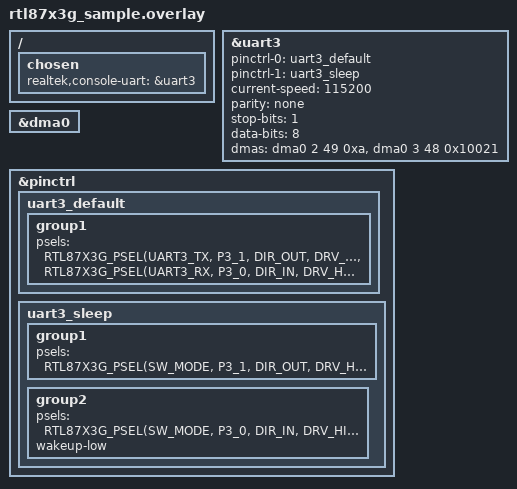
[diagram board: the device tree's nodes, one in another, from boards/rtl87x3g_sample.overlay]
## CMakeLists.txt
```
#
# Copyright (c) 2026, Realtek Semiconductor Corporation
#
# SPDX-License-Identifier: LicenseRef-Realtek-5-Clause
#

message(STATUS "CMAKELIST FOLDER: ${CMAKE_CURRENT_SOURCE_DIR}")

cmake_minimum_required(VERSION 3.20.0)

#===========version generation===========
include(${CMAKE_CURRENT_SOURCE_DIR}/../../cmake/version_generate.cmake)
generate_version()
#===========version generation===========
#===========post build===========
# post build should be called before find_package
include(${CMAKE_CURRENT_SOURCE_DIR}/../../cmake/post_build.cmake)
rtk_post_build()
#===========post build===========

find_package(Zephyr REQUIRED HINTS $ENV{ZEPHYR_BASE})
project(audio_demo)

FILE(GLOB app_sources src/*.c)
target_sources(app PRIVATE
  ${app_sources}
  )

set(headers 
    #header files from app
	src/
    )
target_sources(app PRIVATE ${ZEPHYR_REALTEK_APP_MODULE_DIR}/common/console/transport/console_uart.c)  

target_include_directories(app PRIVATE ${ZEPHYR_REALTEK_APP_MODULE_DIR}/common/console/transport) 

target_precompile_headers(app PUBLIC 
	          ${CMAKE_CURRENT_SOURCE_DIR}/src/app_flags.h
			  )
    
target_include_directories(app PRIVATE src)

target_compile_definitions(app PRIVATE CONFIG_SOC_SERIES_RTL8773G=1)
```

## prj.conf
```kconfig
CONFIG_HEAP_MEM_POOL_SIZE=2048
CONFIG_SERIAL=y
CONFIG_UART_ASYNC_API=y
CONFIG_REALTEK_SUBSYS_AUDIO=y
CONFIG_REALTEK_SUBSYS_BTM=y
CONFIG_REALTEK_SUBSYS_CONSOLE=y
CONFIG_REALTEK_SUBSYS_REMOTE=y
CONFIG_REALTEK_SUBSYS_SYSM=y
```

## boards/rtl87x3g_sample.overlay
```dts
/*
 * Copyright(c) 2024, Realtek Semiconductor Corporation.
 *
 * SPDX-License-Identifier: Apache-2.0
 */

/ {
    chosen {
        /* Route the RTK console transport onto uart3 through the Zephyr async
         * UART driver. Change this phandle to move the console to any UART. */
        realtek,console-uart = &uart3;
    };
};

&uart3 {
    pinctrl-0 = <&uart3_default>;
    pinctrl-1 = <&uart3_sleep>;
    pinctrl-names = "default", "sleep";
    status = "okay";
    current-speed = <115200>;
    parity = "none";
    stop-bits = "1";
    data-bits = <8>;
    dmas = <&dma0 2 49 0xa>, <&dma0 3 48 0x10021>;
    dma-names = "rx", "tx";
};
 
&dma0 {
    status = "okay";
};
 
&pinctrl
{
    uart3_default:uart3_default {
        group1 {
            psels = <RTL87X3G_PSEL(UART3_TX, P3_1, DIR_OUT, DRV_HIGH, PULL_UP)>,
            <RTL87X3G_PSEL(UART3_RX, P3_0, DIR_IN, DRV_HIGH, PULL_UP)>;
        };
    };
 
    uart3_sleep:uart3_sleep {
        group1 {
            psels = <RTL87X3G_PSEL(SW_MODE, P3_1, DIR_OUT, DRV_HIGH, PULL_UP)>;
        };
        group2 {
            psels = <RTL87X3G_PSEL(SW_MODE, P3_0, DIR_IN, DRV_HIGH, PULL_UP)>;
            wakeup-low;
        };
    };
};
```

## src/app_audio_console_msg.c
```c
/*
 * Copyright (c) 2026, Realtek Semiconductor Corporation
 *
 * SPDX-License-Identifier: LicenseRef-Realtek-5-Clause
 */

#include "trace.h"
#include "bt_types.h"
#include "os_mem.h"
#include "app_msg.h"
#include "app_console_msg.h"
#include "app_audio_demo_console.h"
#include "app_audio_demo_policy.h"
#include "app_audio_demo_passthrough.h"
#include "app_audio_demo_line_in.h"
#include "app_audio_demo_anc.h"
#include "app_audio_demo_vad.h"
#include "app_audio_demo_pipe.h"
#include "app_audio_demo_track.h"
#include "app_audio_demo_kws.h"

#define LLAPT_SCENARIO_ID     0x00
#define ANC_SCENARIO_ID       0x00

void app_console_handle_msg(T_IO_MSG console_msg)
{
    uint16_t  subtype;
    uint16_t  id;
    uint16_t  action;
    uint8_t  *p;

    p       = console_msg.u.buf;
    subtype = console_msg.subtype;

    switch (subtype)
    {
    case IO_MSG_CONSOLE_STRING_RX:
        LE_STREAM_TO_UINT16(id, p);
        LE_STREAM_TO_UINT8(action, p);

        if (id == AUDIO_ID)
        {

        }
        else if (id == NOTIFICATION_ID)
        {
            switch (action)
            {
            case AUDIO_DEMO_ACTION_RING_TONE_PLAY:
                app_audio_notification_play(0x01, false, true);
                break;

            case AUDIO_DEMO_ACTION_VOICE_PROMPT_PLAY:
                app_audio_notification_play(0x85, false, true);
                break;

            default:
                break;
            }
        }
        else if (id == APT_ID)
        {
            switch (action)
            {
            case AUDIO_DEMO_ACTION_APT_PLAY:
                app_audio_normal_apt_enable();
                break;

            case AUDIO_DEMO_ACTION_APT_STOP:
                app_audio_normal_apt_disable();
                break;

            default:
                break;
            }
        }
        else if (id == LLAPT_ID)
        {
            switch (action)
            {
            case AUDIO_DEMO_ACTION_LLAPT_PLAY:
                app_audio_llapt_enable(LLAPT_SCENARIO_ID);
                break;

            case AUDIO_DEMO_ACTION_LLAPT_STOP:
                app_audio_llapt_disable();
                break;

            default:
                break;
            }
        }
        else if (id == LINE_ID)
        {
            switch (action)
            {
            case AUDIO_DEMO_ACTION_LINE_START:
                {
                    uint32_t device_out;
                    uint32_t device_in;
                    LE_STREAM_TO_UINT32(device_out, p);
                    LE_STREAM_TO_UINT32(device_in, p);

                    app_audio_line_start(device_out | device_in);
                }
                break;

            case AUDIO_DEMO_ACTION_LINE_STOP:
                app_audio_line_stop();
                break;

            default:
                break;
            }
        }
        else if (id == ANC_ID)
        {
            switch (action)
            {
            case AUDIO_DEMO_ACTION_ANC_ENABLE:
                app_audio_anc_enable(ANC_SCENARIO_ID);
                break;

            case AUDIO_DEMO_ACTION_ANC_DISABLE:
                app_audio_anc_disable();
                break;

            default:
                break;
            }
        }
        else if (id == VAD_ID)
        {
            switch (action)
            {
            case AUDIO_DEMO_ACTION_VAD_ENABLE:
                {
                    uint8_t  vad_type;
                    uint8_t  bit_width;
                    uint16_t frame_length;

                    LE_STREAM_TO_UINT8(vad_type, p);
                    LE_STREAM_TO_UINT8(bit_width, p);
                    LE_STREAM_TO_UINT16(frame_length, p);

                    app_audio_vad_enable(vad_type, bit_width, frame_length);
                }
                break;

            case AUDIO_DEMO_ACTION_VAD_DISABLE:
                app_audio_vad_disable();
                break;

            default:
                break;
            }
        }
        else if (id == KWS_ID)
        {
            switch (action)
            {
            case AUDIO_DEMO_ACTION_KWS_ENABLE:
                app_audio_kws_enable();
                break;

            case AUDIO_DEMO_ACTION_KWS_DISABLE:
                app_audio_kws_disable();
                break;

            default:
                break;
            }
        }
        else if (id == PIPE_ID)
        {
            switch (action)
            {
            case AUDIO_DEMO_ACTION_PIPE_CREATE:
                {
                    uint8_t src_type;
                    uint8_t snk_type;

                    LE_STREAM_TO_UINT8(src_type, p);
                    LE_STREAM_TO_UINT8(snk_type, p);

                    app_audio_pipe_create(src_type, snk_type);
                }
                break;

            case AUDIO_DEMO_ACTION_PIPE_START:
                app_audio_pipe_start();
                break;

            case AUDIO_DEMO_ACTION_PIPE_STOP:
                app_audio_pipe_stop();
                break;

            case AUDIO_DEMO_ACTION_PIPE_RELEASE:
                app_audio_pipe_release();
                break;

            default:
                break;
            }
        }
        else if (id == TRACK_ID)
        {
            switch (action)
            {
            case AUDIO_DEMO_ACTION_TRACK_CREATE:
                {
                    uint8_t stream_type;
                    uint8_t format_type;
                    uint8_t volume_out;
                    uint8_t volume_in;

                    LE_STREAM_TO_UINT8(stream_type, p);
                    LE_STREAM_TO_UINT8(format_type, p);
                    LE_STREAM_TO_UINT8(volume_out, p);
                    LE_STREAM_TO_UINT8(volume_in, p);

                    app_audio_track_create(stream_type,
                                           format_type,
                                           volume_out,
                                           volume_in);
                }
                break;

            case AUDIO_DEMO_ACTION_TRACK_START:
                app_audio_track_start();
                break;

            case AUDIO_DEMO_ACTION_TRACK_STOP:
                app_audio_track_stop();
                break;

            case AUDIO_DEMO_ACTION_TRACK_PAUSE:
                app_audio_track_pause();
                break;

            case AUDIO_DEMO_ACTION_TRACK_RESTART:
                app_audio_track_restart();
                break;

            case AUDIO_DEMO_ACTION_TRACK_RELEASE:
                app_audio_track_release();
                break;

            case AUDIO_DEMO_ACTION_TRACK_VOLUME_OUT_SET:
                {
                    uint8_t volume_out;

                    LE_STREAM_TO_UINT8(volume_out, p);

                    app_audio_track_volume_out_set(volume_out);
                }
                break;

            case AUDIO_DEMO_ACTION_TRACK_VOLUME_OUT_MUTE:
                app_audio_track_volume_out_mute();
                break;

            case AUDIO_DEMO_ACTION_TRACK_VOLUME_OUT_UNMUTE:
                app_audio_track_volume_out_unmute();
                break;

            default:
                break;
            }
        }

        os_mem_free(console_msg.u.buf);
        break;

    default:
        break;
    }
}
```

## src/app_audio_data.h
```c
/*
 * Copyright (c) 2026, Realtek Semiconductor Corporation
 *
 * SPDX-License-Identifier: LicenseRef-Realtek-5-Clause
 */

#ifndef _APP_SBC_DATA_H_
#define _APP_SBC_DATA_H_

#include <stdint.h>

extern const uint8_t sbc_data[];
extern uint32_t sbc_data_len;
extern const uint8_t msbc_data[];
extern uint32_t msbc_data_len;
extern const uint8_t lc3_data[];
extern uint32_t lc3_data_len;
extern const uint8_t pcm_data[];
extern uint32_t pcm_data_len;

#endif
```

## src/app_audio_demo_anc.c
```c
/*
 * Copyright (c) 2026, Realtek Semiconductor Corporation
 *
 * SPDX-License-Identifier: LicenseRef-Realtek-5-Clause
 */

#include "trace.h"
#include "anc.h"
#include "app_audio_demo_anc.h"

static T_ANC_SM_STATE anc_state = ANC_STOPPED;

bool app_audio_anc_enable(uint8_t scenario_id)
{
    if (anc_state != ANC_STARTED)
    {
        anc_state = ANC_STARTING;
        return anc_enable(scenario_id);
    }
    return false;
}

bool app_audio_anc_disable(void)
{
    if (anc_state != ANC_STOPPED)
    {
        anc_state = ANC_STOPPING;
        return anc_disable();
    }
    return false;
}
```

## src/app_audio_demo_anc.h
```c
/*
 * Copyright (c) 2026, Realtek Semiconductor Corporation
 *
 * SPDX-License-Identifier: LicenseRef-Realtek-5-Clause
 */

#ifndef _APP_AUDIO_DEMO_ANC_H_
#define _APP_AUDIO_DEMO_ANC_H_

#include <stdint.h>
#include <stdbool.h>

#ifdef __cplusplus
extern "C" {
#endif /* __cplusplus */

typedef enum t_anc_sm_state
{
    ANC_STOPPED,
    ANC_STARTING,
    ANC_STARTED,
    ANC_STOPPING,
} T_ANC_SM_STATE;

/** @defgroup APP_AUDIO_DEMO_ANC Audio Anc
* @brief APP Audio Anc
* @{
*/

/*============================================================================*
 *                         Macros
 *============================================================================*/
/** @addtogroup APP_AUDIO_DEMO_ANC_Exported_Macros Audio Anc Exported Macros
  * @brief
  * @{
  */



/** End of APP_AUDIO_DEMO_ANC_Exported_Macros
* @}
*/

/*============================================================================*
 *                         Functions
 *============================================================================*/
/** @defgroup APP_AUDIO_DEMO_ANC_Exported_Functions Audio Anc Exported Functions
  * @brief
  * @{
  */

/**
    * @brief  Start/Stop Audio Anc
    * @param  void
    * @return bool
    */
bool app_audio_anc_enable(uint8_t);
bool app_audio_anc_disable(void);


/** @} End of APP_AUDIO_DEMO_ANC_Exported_Functions */

/** @} End of APP_AUDIO_DEMO_ANC */

#ifdef __cplusplus
}
#endif /* __cplusplus */

#endif /* _APP_AUDIO_DEMO_ANC_H_ */
```

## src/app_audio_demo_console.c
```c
/*
 * Copyright (c) 2026, Realtek Semiconductor Corporation
 *
 * SPDX-License-Identifier: LicenseRef-Realtek-5-Clause
 */

#include <stdio.h>
#include <stdint.h>
#include <stdbool.h>
#include <string.h>
#include <stdlib.h>
#include "trace.h"
#include "os_mem.h"
#include "cli.h"
#include "bt_types.h"
#include "app_audio_io_msg.h"
#include "app_audio_demo_console.h"

bool app_audio_demo_send_msg(T_IO_CONSOLE subtype, void *param_buf)
{
    T_IO_MSG msg;

    msg.type    = IO_MSG_TYPE_CONSOLE;
    msg.subtype = subtype;
    msg.u.buf   = param_buf;

    return app_io_send_msg(&msg);
}

bool console_notification(const char *cmd_str, char *buf, size_t buf_len)
{
    char       *subcmd;
    char       *p_param;
    int32_t     param_num;
    uint32_t    param_len;
    uint8_t     action;
    void       *param_buf;

    param_num = cli_param_num_get(cmd_str);
    if (param_num < 1)
    {
        subcmd = (char *)cmd_str;
        goto err;
    }

    subcmd = (char *)cli_param_get(cmd_str, 1, &param_len);
    subcmd[param_len] = '\0';

    if (!strcmp(subcmd, "ringtone"))
    {
        if (param_num != 2)
        {
            goto err;
        }

        p_param = subcmd + param_len + 1;
        subcmd = (char *)cli_param_get(p_param, 0, &param_len);

        if (!strcmp(subcmd, "play"))
        {
            action = AUDIO_DEMO_ACTION_RING_TONE_PLAY;
        }
    }
    else if (!strcmp(subcmd, "vp"))
    {
        if (param_num != 2)
        {
            goto err;
        }

        p_param = subcmd + param_len + 1;
        subcmd = (char *)cli_param_get(p_param, 0, &param_len);

        if (!strcmp(subcmd, "play"))
        {
            action = AUDIO_DEMO_ACTION_VOICE_PROMPT_PLAY;
        }
    }
    else
    {
        goto err;
    }

    param_buf = malloc(40);
    if (param_buf != NULL)
    {
        uint8_t    *p;

        p = param_buf;
        LE_UINT16_TO_STREAM(p, NOTIFICATION_ID);
        LE_UINT8_TO_STREAM(p, action);

        if (app_audio_demo_send_msg(IO_MSG_CONSOLE_STRING_RX, param_buf) == false)
        {
            free(param_buf);
            goto err;
        }

        snprintf(buf, buf_len, "notification %s from audio demo.\r\n", subcmd);
    }

    return false;

err:
    snprintf(buf, buf_len, "Invalid param %s (notification play/stop).\r\n", subcmd);
    return false;
}

bool console_apt(const char *cmd_str, char *buf, size_t buf_len)
{
    char       *subcmd;
    int32_t     param_num;
    uint32_t    param_len;
    uint8_t     action;
    void       *param_buf;

    param_num = cli_param_num_get(cmd_str);
    if (param_num < 1)
    {
        subcmd = (char *)cmd_str;
        goto err;
    }

    subcmd = (char *)cli_param_get(cmd_str, 1, &param_len);
    subcmd[param_len] = '\0';

    if (!strcmp(subcmd, "enable"))
    {
        action = AUDIO_DEMO_ACTION_APT_PLAY;
    }
    else if (!strcmp(subcmd, "disable"))
    {
        action = AUDIO_DEMO_ACTION_APT_STOP;
    }
    else
    {
        goto err;
    }

    param_buf = malloc(40);
    if (param_buf != NULL)
    {
        uint8_t    *p;

        p = param_buf;
        LE_UINT16_TO_STREAM(p, APT_ID);
        LE_UINT8_TO_STREAM(p, action);

        if (app_audio_demo_send_msg(IO_MSG_CONSOLE_STRING_RX, param_buf) == false)
        {
            free(param_buf);
            goto err;
        }

        snprintf(buf, buf_len, "apt %s from audio demo.\r\n", subcmd);
    }

    return false;

err:
    snprintf(buf, buf_len, "Invalid param %s (apt enable/disable).\r\n", subcmd);
    return false;
}

bool console_llapt(const char *cmd_str, char *buf, size_t buf_len)
{
    char       *subcmd;
    int32_t     param_num;
    uint32_t    param_len;
    uint8_t     action;
    void       *param_buf;

    param_num = cli_param_num_get(cmd_str);
    if (param_num < 1)
    {
        subcmd = (char *)cmd_str;
        goto err;
    }

    subcmd = (char *)cli_param_get(cmd_str, 1, &param_len);
    subcmd[param_len] = '\0';

    if (!strcmp(subcmd, "enable"))
    {
        action = AUDIO_DEMO_ACTION_LLAPT_PLAY;
    }
    else if (!strcmp(subcmd, "disable"))
    {
        action = AUDIO_DEMO_ACTION_LLAPT_STOP;
    }
    else
    {
        goto err;
    }

    param_buf = malloc(40);
    if (param_buf != NULL)
    {
        uint8_t    *p;

        p = param_buf;
        LE_UINT16_TO_STREAM(p, LLAPT_ID);
        LE_UINT8_TO_STREAM(p, action);

        if (app_audio_demo_send_msg(IO_MSG_CONSOLE_STRING_RX, param_buf) == false)
        {
            free(param_buf);
            goto err;
        }

        snprintf(buf, buf_len, "llapt %s from audio demo.\r\n", subcmd);
    }

    return false;

err:
    snprintf(buf, buf_len, "Invalid param %s (llapt enable/disable).\r\n", subcmd);
    return false;
}

bool console_line(const char *cmd_str, char *buf, size_t buf_len)
{
    char       *subcmd;
    char       *p_param;
    int32_t     param_num;
    uint32_t    param_len;
    uint32_t    device_out;
    uint32_t    device_in;
    uint8_t     action;
    void       *param_buf;

    param_num = cli_param_num_get(cmd_str);
    if (param_num < 1)
    {
        subcmd = (char *)cmd_str;
        goto err;
    }

    subcmd = (char *)cli_param_get(cmd_str, 1, &param_len);
    subcmd[param_len] = '\0';

    if (!strcmp(subcmd, "start"))
    {
        if (param_num != 3)
        {
            goto err;
        }

        p_param = subcmd + param_len + 1;

        device_out = (uint32_t)strtol(cli_param_get(p_param, 0, &param_len), NULL, 0);
        device_in = (uint32_t)strtol(cli_param_get(p_param, 1, &param_len), NULL, 0);

        action = AUDIO_DEMO_ACTION_LINE_START;
    }
    else if (!strcmp(subcmd, "stop"))
    {
        action = AUDIO_DEMO_ACTION_LINE_STOP;
    }
    else
    {
        goto err;
    }

    param_buf = malloc(40);
    if (param_buf != NULL)
    {
        uint8_t    *p;

        p = param_buf;
        LE_UINT16_TO_STREAM(p, LINE_ID);
        LE_UINT8_TO_STREAM(p, action);
        LE_UINT32_TO_STREAM(p, device_out);
        LE_UINT32_TO_STREAM(p, device_in);

        if (app_audio_demo_send_msg(IO_MSG_CONSOLE_STRING_RX, param_buf) == false)
        {
            free(param_buf);
            goto err;
        }

        snprintf(buf, buf_len, "line %s from audio demo.\r\n", subcmd);
    }

    return false;

err:
    snprintf(buf, buf_len, "Invalid param %s (line start/stop).\r\n", subcmd);
    return false;
}

bool console_anc(const char *cmd_str, char *buf, size_t buf_len)
{
    char       *subcmd;
    int32_t     param_num;
    uint32_t    param_len;
    uint8_t     action;
    void       *param_buf;

    param_num = cli_param_num_get(cmd_str);
    if (param_num < 1)
    {
        subcmd = (char *)cmd_str;
        goto err;
    }

    subcmd = (char *)cli_param_get(cmd_str, 1, &param_len);
    subcmd[param_len] = '\0';

    if (!strcmp(subcmd, "enable"))
    {
        action = AUDIO_DEMO_ACTION_ANC_ENABLE;
    }
    else if (!strcmp(subcmd, "disable"))
    {
        action = AUDIO_DEMO_ACTION_ANC_DISABLE;
    }
    else
    {
        goto err;
    }

    param_buf = malloc(40);
    if (param_buf != NULL)
    {
        uint8_t    *p;

        p = param_buf;
        LE_UINT16_TO_STREAM(p, ANC_ID);
        LE_UINT8_TO_STREAM(p, action);

        if (app_audio_demo_send_msg(IO_MSG_CONSOLE_STRING_RX, param_buf) == false)
        {
            free(param_buf);
            goto err;
        }

        snprintf(buf, buf_len, "anc %s from audio demo.\r\n", subcmd);
    }

    return false;

err:
    snprintf(buf, buf_len, "Invalid param %s (anc enable/disable).\r\n", subcmd);
    return false;
}

bool console_vad(const char *cmd_str, char *buf, size_t buf_len)
{
    char       *subcmd;
    char       *p_param;
    int32_t     param_num;
    uint32_t    param_len;
    uint8_t     action;
    uint8_t     vad_type;
    uint8_t     bit_width;
    uint16_t    frame_length;
    void       *param_buf;

    param_num = cli_param_num_get(cmd_str);
    if (param_num < 1)
    {
        subcmd = (char *)cmd_str;
        goto err;
    }

    subcmd = (char *)cli_param_get(cmd_str, 1, &param_len);
    subcmd[param_len] = '\0';

    if (!strcmp(subcmd, "enable"))
    {
        if (param_num != 4)
        {
            goto err;
        }

        p_param = subcmd + param_len + 1;

        vad_type     = (uint8_t)strtol(cli_param_get(p_param, 0, &param_len), NULL, 0);
        bit_width    = (uint8_t)strtol(cli_param_get(p_param, 1, &param_len), NULL, 0);
        frame_length = (uint16_t)strtol(cli_param_get(p_param, 2, &param_len), NULL, 0);

        action = AUDIO_DEMO_ACTION_VAD_ENABLE;
    }
    else if (!strcmp(subcmd, "disable"))
    {
        action = AUDIO_DEMO_ACTION_VAD_DISABLE;
    }
    else
    {
        goto err;
    }

    param_buf = malloc(40);
    if (param_buf != NULL)
    {
        uint8_t    *p;

        p = param_buf;
        LE_UINT16_TO_STREAM(p, VAD_ID);
        LE_UINT8_TO_STREAM(p, action);
        LE_UINT8_TO_STREAM(p, vad_type);
        LE_UINT8_TO_STREAM(p, bit_width);
        LE_UINT16_TO_STREAM(p, frame_length);

        if (app_audio_demo_send_msg(IO_MSG_CONSOLE_STRING_RX, param_buf) == false)
        {
            free(param_buf);
            goto err;
        }

        snprintf(buf, buf_len, "vad %s from audio demo.\r\n", subcmd);
    }

    return false;

err:
    snprintf(buf, buf_len, "Invalid param %s (vad enable/disable).\r\n", subcmd);
    return false;
}

bool console_kws(const char *cmd_str, char *buf, size_t buf_len)
{
    char       *subcmd;
    int32_t     param_num;
    uint32_t    param_len;
    uint8_t     action;
    void       *param_buf;

    param_num = cli_param_num_get(cmd_str);
    if (param_num < 1)
    {
        subcmd = (char *)cmd_str;
        goto err;
    }

    subcmd = (char *)cli_param_get(cmd_str, 1, &param_len);
    subcmd[param_len] = '\0';

    if (!strcmp(subcmd, "enable"))
    {
        action = AUDIO_DEMO_ACTION_KWS_ENABLE;
    }
    else if (!strcmp(subcmd, "disable"))
    {
        action = AUDIO_DEMO_ACTION_KWS_DISABLE;
    }
    else
    {
        goto err;
    }

    param_buf = malloc(40);
    if (param_buf != NULL)
    {
        uint8_t    *p;

        p = param_buf;
        LE_UINT16_TO_STREAM(p, KWS_ID);
        LE_UINT8_TO_STREAM(p, action);

        if (app_audio_demo_send_msg(IO_MSG_CONSOLE_STRING_RX, param_buf) == false)
        {
            free(param_buf);
            goto err;
        }

        snprintf(buf, buf_len, "kws %s from audio demo.\r\n", subcmd);
    }

    return false;

err:
    snprintf(buf, buf_len, "Invalid param %s (kws enable/disable).\r\n", subcmd);
    return false;
}

bool console_pipe(const char *cmd_str, char *buf, size_t buf_len)
{
    char       *subcmd;
    char       *p_param;
    int32_t     param_num;
    uint32_t    param_len;
    uint8_t     action;
    uint8_t     src_type;
    uint8_t     snk_type;
    void       *param_buf;

    param_num = cli_param_num_get(cmd_str);
    if (param_num < 1)
    {
        subcmd = (char *)cmd_str;
        goto err;
    }

    subcmd = (char *)cli_param_get(cmd_str, 1, &param_len);
    subcmd[param_len] = '\0';

    if (!strcmp(subcmd, "create"))
    {
        if (param_num != 3)
        {
            goto err;
        }

        p_param = subcmd + param_len + 1;

        src_type = (uint8_t)strtol(cli_param_get(p_param, 0, &param_len), NULL, 0);
        snk_type = (uint8_t)strtol(cli_param_get(p_param, 1, &param_len), NULL, 0);

        action = AUDIO_DEMO_ACTION_PIPE_CREATE;
    }
    else if (!strcmp(subcmd, "start"))
    {
        action = AUDIO_DEMO_ACTION_PIPE_START;
    }
    else if (!strcmp(subcmd, "stop"))
    {
        action = AUDIO_DEMO_ACTION_PIPE_STOP;
    }
    else if (!strcmp(subcmd, "release"))
    {
        action = AUDIO_DEMO_ACTION_PIPE_RELEASE;
    }
    else
    {
        goto err;
    }

    param_buf = malloc(40);
    if (param_buf != NULL)
    {
        uint8_t    *p;

        p = param_buf;
        LE_UINT16_TO_STREAM(p, PIPE_ID);
        LE_UINT8_TO_STREAM(p, action);
        LE_UINT8_TO_STREAM(p, src_type);
        LE_UINT8_TO_STREAM(p, snk_type);

        if (app_audio_demo_send_msg(IO_MSG_CONSOLE_STRING_RX, param_buf) == false)
        {
            free(param_buf);
            goto err;
        }

        snprintf(buf, buf_len, "pipe %s from audio demo.\r\n", subcmd);
    }

    return false;

err:
    snprintf(buf, buf_len, "Invalid param %s .\r\n", subcmd);
    return false;
}

bool console_track(const char *cmd_str, char *buf, size_t buf_len)
{
    char       *subcmd;
    char       *p_param;
    int32_t     param_num;
    uint32_t    param_len;
    uint8_t     action;
    uint8_t     stream_type;
    uint8_t     format_type;
    uint8_t     volume_out;
    uint8_t     volume_in;
    void       *param_buf;

    param_num = cli_param_num_get(cmd_str);
    if (param_num < 1)
    {
        subcmd = (char *)cmd_str;
        goto err;
    }

    subcmd = (char *)cli_param_get(cmd_str, 1, &param_len);
    subcmd[param_len] = '\0';

    if (!strcmp(subcmd, "create"))
    {
        if (param_num != 5)
        {
            goto err;
        }

        p_param = subcmd + param_len + 1;

        stream_type = (uint8_t)strtol(cli_param_get(p_param, 0, &param_len), NULL, 0);
        format_type = (uint8_t)strtol(cli_param_get(p_param, 1, &param_len), NULL, 0);
        volume_out = (uint8_t)strtol(cli_param_get(p_param, 2, &param_len), NULL, 0);
        volume_in = (uint8_t)strtol(cli_param_get(p_param, 3, &param_len), NULL, 0);

        action = AUDIO_DEMO_ACTION_TRACK_CREATE;
    }
    else if (!strcmp(subcmd, "start"))
    {
        action = AUDIO_DEMO_ACTION_TRACK_START;
    }
    else if (!strcmp(subcmd, "stop"))
    {
        action = AUDIO_DEMO_ACTION_TRACK_STOP;
    }
    else if (!strcmp(subcmd, "pause"))
    {
        action = AUDIO_DEMO_ACTION_TRACK_PAUSE;
    }
    else if (!strcmp(subcmd, "restart"))
    {
        action = AUDIO_DEMO_ACTION_TRACK_RESTART;
    }
    else if (!strcmp(subcmd, "release"))
    {
        action = AUDIO_DEMO_ACTION_TRACK_RELEASE;
    }
    else if (!strcmp(subcmd, "vol_out_set"))
    {
        if (param_num != 2)
        {
            goto err;
        }

        p_param = subcmd + param_len + 1;

        volume_out = (uint8_t)strtol(cli_param_get(p_param, 0, &param_len), NULL, 0);

        action = AUDIO_DEMO_ACTION_TRACK_VOLUME_OUT_SET;
    }
    else if (!strcmp(subcmd, "vol_out_mute"))
    {
        action = AUDIO_DEMO_ACTION_TRACK_VOLUME_OUT_MUTE;
    }
    else if (!strcmp(subcmd, "vol_out_unmute"))
    {
        action = AUDIO_DEMO_ACTION_TRACK_VOLUME_OUT_UNMUTE;
    }
    else
    {
        goto err;
    }

    param_buf = malloc(40);
    if (param_buf != NULL)
    {
        uint8_t    *p;

        p = param_buf;
        LE_UINT16_TO_STREAM(p, TRACK_ID);
        LE_UINT8_TO_STREAM(p, action);
        if (action == AUDIO_DEMO_ACTION_TRACK_CREATE)
        {
            LE_UINT8_TO_STREAM(p, stream_type);
            LE_UINT8_TO_STREAM(p, format_type);
            LE_UINT8_TO_STREAM(p, volume_out);
            LE_UINT8_TO_STREAM(p, volume_in);
        }
        else if (action == AUDIO_DEMO_ACTION_TRACK_VOLUME_OUT_SET)
        {
            LE_UINT8_TO_STREAM(p, volume_out);
        }

        if (app_audio_demo_send_msg(IO_MSG_CONSOLE_STRING_RX, param_buf) == false)
        {
            free(param_buf);
            goto err;
        }

        snprintf(buf, buf_len, "track %s from audio demo.\r\n", subcmd);
    }

    return false;

err:
    snprintf(buf, buf_len, "Invalid param %s .\r\n", subcmd);
    return false;
}

#if (NOTIFICATION_DEMO_SUPPORT == 1)
static T_CLI_CMD audio_demo_notification_cmd =
{
    NULL,                   /* Next command pointed to NULL. */
    NULL,                   /* Next subcommand. */
    "notification",         /* The command string to type. */
    "\r\nnotification:\r\n audio demo start\r\n\r\n",
    console_notification,   /* The function to run. */
    -1                      /* Zero or more parameters are expected. */
};
#endif

#if (APT_DEMO_SUPPORT == 1)
static T_CLI_CMD audio_demo_apt_cmd =
{
    NULL,           /* Next command pointed to NULL. */
    NULL,           /* Next subcommand. */
    "apt",          /* The command string to type. */
    "\r\napt:\r\n apt demo start\r\n\r\n",
    console_apt,    /* The function to run. */
    -1              /* Zero or more parameters are expected. */
};
#endif

#if (LLAPT_DEMO_SUPPORT == 1)
static T_CLI_CMD audio_demo_llapt_cmd =
{
    NULL,            /* Next command pointed to NULL. */
    NULL,            /* Next subcommand. */
    "llapt",         /* The command string to type. */
    "\r\nllapt:\r\n llapt demo start\r\n\r\n",
    console_llapt,   /* The function to run. */
    -1               /* Zero or more parameters are expected. */
};
#endif

#if (LINE_IN_DEMO_SUPPORT == 1)
static T_CLI_CMD audio_demo_line_in_cmd =
{
    NULL,           /* Next command pointed to NULL. */
    NULL,           /* Next subcommand. */
    "line",         /* The command string to type. */
    "\r\nline:\r\n line demo start\r\n\r\n",
    console_line,   /* The function to run. */
    -1              /* Zero or more parameters are expected. */
};
#endif

#if (ANC_DEMO_SUPPORT == 1)
static T_CLI_CMD audio_demo_anc_cmd =
{
    NULL,           /* Next command pointed to NULL. */
    NULL,           /* Next subcommand. */
    "anc",          /* The command string to type. */
    "\r\nanc:\r\n anc demo start\r\n\r\n",
    console_anc,    /* The function to run. */
    -1              /* Zero or more parameters are expected. */
};
#endif

#if (VAD_DEMO_SUPPORT == 1)
static T_CLI_CMD audio_demo_vad_cmd =
{
    NULL,           /* Next command pointed to NULL. */
    NULL,           /* Next subcommand. */
    "vad",          /* The command string to type. */
    "\r\nvad:\r\n vad demo start\r\n\r\n",
    console_vad,    /* The function to run. */
    -1              /* Zero or more parameters are expected. */
};
#endif

#if (KWS_DEMO_SUPPORT == 1)
static T_CLI_CMD audio_demo_kws_cmd =
{
    NULL,           /* Next command pointed to NULL. */
    NULL,           /* Next subcommand. */
    "kws",          /* The command string to type. */
    "\r\nkws:\r\n kws demo start\r\n\r\n",
    console_kws,    /* The function to run. */
    -1              /* Zero or more parameters are expected. */
};
#endif

#if (AUDIO_PIPE_DEMO_SUPPORT == 1)
static T_CLI_CMD audio_demo_pipe_cmd =
{
    NULL,           /* Next command pointed to NULL. */
    NULL,           /* Next subcommand. */
    "pipe",         /* The command string to type. */
    "\r\npipe:\r\n audio pipe demo start\r\n\r\n",
    console_pipe,   /* The function to run. */
    -1              /* Zero or more parameters are expected. */
};
#endif

#if (AUDIO_TRACK_DEMO_SUPPORT == 1)
static T_CLI_CMD audio_demo_track_cmd =
{
    NULL,            /* Next command pointed to NULL. */
    NULL,            /* Next subcommand. */
    "track",         /* The command string to type. */
    "\r\ntrack:\r\n audio track demo start\r\n\r\n",
    console_track,   /* The function to run. */
    -1               /* Zero or more parameters are expected. */
};
#endif

void app_audio_demo_cmd_register(void)
{
#if (NOTIFICATION_DEMO_SUPPORT == 1)
    cli_cmd_register(&audio_demo_notification_cmd);
#endif

#if (APT_DEMO_SUPPORT == 1)
    cli_cmd_register(&audio_demo_apt_cmd);
#endif

#if (LLAPT_DEMO_SUPPORT == 1)
    cli_cmd_register(&audio_demo_llapt_cmd);
#endif

#if (LINE_IN_DEMO_SUPPORT == 1)
    cli_cmd_register(&audio_demo_line_in_cmd);
#endif

#if (ANC_DEMO_SUPPORT == 1)
    cli_cmd_register(&audio_demo_anc_cmd);
#endif

#if (VAD_DEMO_SUPPORT == 1)
    cli_cmd_register(&audio_demo_vad_cmd);
#endif

#if (KWS_DEMO_SUPPORT == 1)
    cli_cmd_register(&audio_demo_kws_cmd);
#endif

#if (AUDIO_PIPE_DEMO_SUPPORT == 1)
    cli_cmd_register(&audio_demo_pipe_cmd);
#endif

#if (AUDIO_TRACK_DEMO_SUPPORT == 1)
    cli_cmd_register(&audio_demo_track_cmd);
#endif
}
```

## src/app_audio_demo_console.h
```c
/*
 * Copyright (c) 2026, Realtek Semiconductor Corporation
 *
 * SPDX-License-Identifier: LicenseRef-Realtek-5-Clause
 */

#ifndef _AUDIO_DEMO_CONSOLE_H_
#define _AUDIO_DEMO_CONSOLE_H_

#ifdef __cplusplus
extern "C" {
#endif /* __cplusplus */

/** @brief Audio demo command */
typedef enum
{
    AUDIO_ID              = 0x0000,
    VOICE_ID              = 0x0001,
    RECORD_ID             = 0x0002,
    LINE_ID               = 0x0003,
    NOTIFICATION_ID       = 0x0004,
    APT_ID                = 0x0006,
    LLAPT_ID              = 0x0007,
    ANC_ID                = 0x0008,
    VAD_ID                = 0x0009,
    PIPE_ID               = 0x000A,
    TRACK_ID              = 0x000B,
    KWS_ID                = 0x000C,
} T_AUDIO_DEMO_CMD_ID;

#define AUDIO_DEMO_ACTION_RING_TONE_PLAY           0x01
#define AUDIO_DEMO_ACTION_VOICE_PROMPT_PLAY        0x02
#define AUDIO_DEMO_ACTION_APT_PLAY                 0x03
#define AUDIO_DEMO_ACTION_APT_STOP                 0x04
#define AUDIO_DEMO_ACTION_LLAPT_PLAY               0x05
#define AUDIO_DEMO_ACTION_LLAPT_STOP               0x06
#define AUDIO_DEMO_ACTION_LINE_START               0x07
#define AUDIO_DEMO_ACTION_LINE_STOP                0x08
#define AUDIO_DEMO_ACTION_ANC_ENABLE               0x09
#define AUDIO_DEMO_ACTION_ANC_DISABLE              0x0A
#define AUDIO_DEMO_ACTION_VAD_ENABLE               0x0B
#define AUDIO_DEMO_ACTION_VAD_DISABLE              0x0C
#define AUDIO_DEMO_ACTION_KWS_ENABLE               0x0D
#define AUDIO_DEMO_ACTION_KWS_DISABLE              0x0E

#define AUDIO_DEMO_ACTION_PIPE_CREATE              0x01
#define AUDIO_DEMO_ACTION_PIPE_START               0x02
#define AUDIO_DEMO_ACTION_PIPE_STOP                0x03
#define AUDIO_DEMO_ACTION_PIPE_RELEASE             0x04

#define AUDIO_DEMO_ACTION_TRACK_CREATE             0x01
#define AUDIO_DEMO_ACTION_TRACK_START              0x02
#define AUDIO_DEMO_ACTION_TRACK_STOP               0x03
#define AUDIO_DEMO_ACTION_TRACK_PAUSE              0x04
#define AUDIO_DEMO_ACTION_TRACK_RESTART            0x05
#define AUDIO_DEMO_ACTION_TRACK_RELEASE            0x06
#define AUDIO_DEMO_ACTION_TRACK_VOLUME_OUT_SET     0x07
#define AUDIO_DEMO_ACTION_TRACK_VOLUME_OUT_MUTE    0x08
#define AUDIO_DEMO_ACTION_TRACK_VOLUME_OUT_UNMUTE  0x09

void app_audio_demo_cmd_register(void);

#ifdef __cplusplus
}
#endif /* __cplusplus */

#endif /* _AUDIO_DEMO_CONSOLE_H_ */
```

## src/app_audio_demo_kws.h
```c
/*
 * Copyright (c) 2026, Realtek Semiconductor Corporation
 *
 * SPDX-License-Identifier: LicenseRef-Realtek-5-Clause
 */

#ifndef _APP_AUDIO_DEMO_KWS_H_
#define _APP_AUDIO_DEMO_KWS_H_

#include <stdint.h>
#include <stdbool.h>

#ifdef __cplusplus
extern "C" {
#endif /* __cplusplus */

typedef enum t_kws_sm_state
{
    KWS_STOPPED,
    KWS_STARTING,
    KWS_STARTED,
    KWS_STOPPING,
} T_KWS_SM_STATE;

/** @defgroup APP_AUDIO_DEMO_KWS Audio Kws
* @brief APP Audio Kws
* @{
*/

/*============================================================================*
 *                         Macros
 *============================================================================*/
/** @addtogroup APP_AUDIO_DEMO_KWS_Exported_Macros Audio Kws Exported Macros
  * @brief
  * @{
  */



/** End of APP_AUDIO_DEMO_KWS_Exported_Macros
* @}
*/

/*============================================================================*
 *                         Functions
 *============================================================================*/
/** @defgroup APP_AUDIO_DEMO_KWS_Exported_Functions Audio Kws Exported Functions
  * @brief
  * @{
  */

/**
    * @brief  Start Audio Kws
    * @param  void
    * @return bool
*/
bool app_audio_kws_enable(void);

/**
    * @brief  Stop Audio Kws
    * @param  void
    * @return bool
*/
bool app_audio_kws_disable(void);


/** @} End of APP_AUDIO_DEMO_KWS_Exported_Functions */

/** @} End of APP_AUDIO_DEMO_KWS */

#ifdef __cplusplus
}
#endif /* __cplusplus */

#endif /* _APP_AUDIO_DEMO_KWS_H_ */
```

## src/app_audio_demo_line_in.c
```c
/*
 * Copyright (c) 2026, Realtek Semiconductor Corporation
 *
 * SPDX-License-Identifier: LicenseRef-Realtek-5-Clause
 */

#include <stdbool.h>
#include "trace.h"
#include "audio.h"
#include "audio_type.h"
#include "audio_line.h"
#include "app_audio_demo_line_in.h"

static T_AUDIO_LINE_HANDLE line_handle;

bool app_audio_line_start(uint32_t device)
{
    line_handle = audio_line_create(device,
                                    48000,
                                    48000);

    if (line_handle != NULL)
    {
        return audio_line_start(line_handle);
    }

    return false;
}

bool app_audio_line_stop(void)
{
    if (line_handle != NULL)
    {
        return audio_line_release(line_handle);
    }

    return false;
}
```

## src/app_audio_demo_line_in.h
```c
/*
 * Copyright (c) 2026, Realtek Semiconductor Corporation
 *
 * SPDX-License-Identifier: LicenseRef-Realtek-5-Clause
 */

#ifndef _APP_AUDIO_DEMO_LINE_IN_H_
#define _APP_AUDIO_DEMO_LINE_IN_H_

#include <stdint.h>
#include <stdbool.h>

#ifdef __cplusplus
extern "C" {
#endif /* __cplusplus */

/** @defgroup APP_AUDIO_DEMO_LINE_IN Audio Line_in
* @brief APP Audio Line_in
* @{
*/

/*============================================================================*
 *                         Macros
 *============================================================================*/
/** @addtogroup APP_AUDIO_DEMO_LINE_IN_Exported_Macros Audio Line_in Exported Macros
  * @brief
  * @{
  */



/** End of APP_AUDIO_DEMO_LINE_IN_Exported_Macros
* @}
*/

/*============================================================================*
 *                         Functions
 *============================================================================*/
/** @defgroup APP_AUDIO_DEMO_LINE_IN_Exported_Functions Audio Line_in Exported Functions
  * @brief
  * @{
  */

/**
    * @brief  Start/Stop Audio Line_in
    * @param  void
    * @return bool
    */
bool app_audio_line_start(uint32_t device);
bool app_audio_line_stop(void);

/** @} End of APP_AUDIO_DEMO_LINE_IN_Exported_Functions */

/** @} End of APP_AUDIO_DEMO_LINE_IN */

#ifdef __cplusplus
}
#endif /* __cplusplus */

#endif /* _APP_AUDIO_DEMO_LINE_IN_H_ */
```

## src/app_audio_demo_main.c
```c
/*
 * Copyright (c) 2026, Realtek Semiconductor Corporation
 *
 * SPDX-License-Identifier: LicenseRef-Realtek-5-Clause
 */

#include <string.h>
#include "rtl876x_pinmux.h"
#include "rtl876x_uart.h"
#include "fmc_api.h"
#include "trace.h"
#include "os_task.h"
#include "os_mem.h"
#include "os_sched.h"
#include "os_msg.h"
#include "gap.h"
#include "gap_br.h"
#include "btm.h"
#include "sysm.h"
#include "remote.h"
#include "audio.h"
#include "audio_probe.h"
#include "app_timer.h"
#include "app_msg.h"
#include "app_audio_io_msg.h"
#include "console_uart.h"
#include "app_audio_demo_console.h"
#include "app_audio_demo_policy.h"
#include "app_audio_demo_passthrough.h"

#if F_APP_HIFI4_SUPPORT
#include "app_buck_tps62860.h"
#include "app_buck_apw7564.h"
#endif

#if CONFIG_SOC_SERIES_RTL8773G
#include "app_module_psram.h"
#endif

/** @defgroup  AUDIO_DEMO_MAIN Audio demo Main
    * @brief Main file to initialize hardware and start task scheduling
    * @{
    */

#define I2C_0_CLK                   P0_0
#define I2C_0_DAT                   P0_1
#define BUCK_PWR_EN                 P5_1

#define BT_AUDIO_DEFAULT_PAGESCAN_WINDOW             0x12
#define BT_AUDIO_DEFAULT_PAGESCAN_INTERVAL           0x800 //0x800
#define BT_AUDIO_DEFAULT_PAGE_TIMEOUT                0x4000
#define BT_AUDIO_DEFAULT_SUPVISIONTIMEOUT            0x1f40 //0x7D00
#define BT_AUDIO_DEFAULT_INQUIRYSCAN_WINDOW          0x12
#define BT_AUDIO_DEFAULT_INQUIRYSCAN_INTERVAL        0x800 //0x1000

#define PLAYBACK_POOL_SIZE                  (13*1024)
#define VOICE_POOL_SIZE                     (2*1024)
#define RECORD_POOL_SIZE                    (1*1024)
#define NOTIFICATION_POOL_SIZE              (8*1024)

#define BT_AUDIO_MAX_NUMBER_OF_GAP_MESSAGE     0x20      //!<  GAP message queue size
#define BT_AUDIO_MAX_NUMBER_OF_IO_MESSAGE      0x20      //!<  IO message queue size
#define BT_AUDIO_MAX_NUMBER_OF_EVENT_MESSAGE   (BT_AUDIO_MAX_NUMBER_OF_GAP_MESSAGE + BT_AUDIO_MAX_NUMBER_OF_IO_MESSAGE)    //!< Event message queue size
#define AUDIO_MAX_NUMBER_OF_APP_TIMER_MODULE   0x10    //!< indicate app timer module size

#define CONSOLE_UART_RX_BUFFER_SIZE         300

void *audio_evt_queue_handle;  //!< Event queue handle
void *audio_io_queue_handle;   //!< IO queue handle

/*============================================================================*
 *                              Functions
 *============================================================================*/

/**
 * @brief    Contains the initialization of framework
 * @return   void
 */
static void framework_init(void)
{
    /* System Manager */
    sys_mgr_init(audio_evt_queue_handle);

    /* RemoteController Manager */
    remote_mgr_init(REMOTE_SESSION_ROLE_SINGLE);

    /* Bluetooth Manager */
    bt_mgr_init();

    /* Audio Manager */
    audio_mgr_init(PLAYBACK_POOL_SIZE, VOICE_POOL_SIZE, RECORD_POOL_SIZE, NOTIFICATION_POOL_SIZE);
}

/**
 * @brief    Contains the initialization of pinmux settings and pad settings
 * @note     All the pinmux settings and pad settings shall be initiated in this function,
 *           but if legacy driver is used, the initialization of pinmux setting and pad setting
 *           should be peformed with the IO initializing.
 * @return   void
 */
void board_init(void)
{
    /* Console UART pins are owned by devicetree (realtek,console-uart / uart3
     * pinctrl); the Zephyr UART driver configures them. Only non-console pins
     * are still set up here. */
    Pinmux_Config(I2C_0_DAT, I2C0_DAT);
    Pinmux_Config(I2C_0_CLK, I2C0_CLK);

    Pad_Config(I2C_0_DAT,
               PAD_PINMUX_MODE, PAD_IS_PWRON, PAD_PULL_NONE, PAD_OUT_DISABLE, PAD_OUT_LOW);
    Pad_Config(I2C_0_CLK,
               PAD_PINMUX_MODE, PAD_IS_PWRON, PAD_PULL_NONE, PAD_OUT_DISABLE, PAD_OUT_LOW);
    Pad_PullConfigValue(I2C_0_DAT, PAD_STRONG_PULL);
    Pad_PullConfigValue(I2C_0_CLK, PAD_STRONG_PULL);
}

/**
 * @brief    Contains the initialization of peripherals
 * @note     Both new architecture driver and legacy driver initialization method can be used
 * @return   void
 */
static void driver_init(void)
{
    T_CONSOLE_PARAM console_param;
    T_CONSOLE_OP    console_op;
    T_CONSOLE_UART_CONFIG console_uart_config;
    memset(&console_param, 0x00, sizeof(T_CONSOLE_PARAM));
    memset(&console_op, 0x00, sizeof(T_CONSOLE_OP));
    memset(&console_uart_config, 0x00, sizeof(T_CONSOLE_UART_CONFIG));

    /* Pinmux, baud rate and wakeup pins are owned by the Zephyr UART driver
     * (devicetree). Only the transport-level parameters are set here. */
    console_uart_config.one_wire_uart_support = false; // one-wire uart not support in zephyr uart
    console_uart_config.callback = NULL;
    console_uart_config.uart_dma_rx_buffer_size = CONSOLE_UART_RX_BUFFER_SIZE;
    console_uart_config_init(&console_uart_config);

    console_param.tx_buf_size   = 512;
    console_param.rx_buf_size   = 512;

    console_op.init = console_uart_init;
    console_op.write = console_uart_write;

    console_init(&console_param, &console_op);
    console_set_mode(CONSOLE_MODE_STRING);

#if F_APP_HIFI4_SUPPORT
    audio_probe_dsp2_exist_set(true);

    if (app_buck_tps62860_init(BUCK_PWR_EN) == true)
    {
        APP_PRINT_TRACE0("driver_init: tps62860 init success");
    }
    else if (app_buck_apw7564_init() == true)
    {
        APP_PRINT_TRACE0("driver_init: apw7564 init success");
    }
    else
    {
        APP_PRINT_ERROR0("driver_init: No invalid external buck recognised, please check the hardware setting!!");
    }
#endif

#if CONFIG_SOC_SERIES_RTL8773G
    app_psram_init();
#endif
}

/**
 * @brief        App task to handle events & messages
 * @param[in]    p_param    Parameters sending to the task
 * @return       void
 */
void audio_demo_main_task(void *p_param)
{
    uint8_t event;

    gap_start_bt_stack(audio_evt_queue_handle, audio_io_queue_handle,
                       BT_AUDIO_MAX_NUMBER_OF_GAP_MESSAGE);

    while (true)
    {
        if (os_msg_recv(audio_evt_queue_handle, &event, 0xFFFFFFFF) == true)
        {
            if (EVENT_GROUP(event) == EVENT_GROUP_IO)
            {
                T_IO_MSG io_msg;

                if (os_msg_recv(audio_io_queue_handle, &io_msg, 0) == true)
                {
                    if (event == EVENT_IO_TO_APP)
                    {
                        app_io_handle_msg(io_msg);
                    }
                }
            }
            else if (EVENT_GROUP(event) == EVENT_GROUP_STACK)
            {
                gap_handle_msg(event);
            }
            else if (EVENT_GROUP(event) == EVENT_GROUP_FRAMEWORK)
            {
                sys_mgr_event_handle(event);
            }
            else if (EVENT_GROUP(event) == EVENT_GROUP_APP)
            {
                app_timer_handle_msg(event);
            }
        }
    }
}

/**
 * @brief    Contains the initialization of all tasks
 * @note     There is only one task in BT Audio APP, thus only one APP task is init here
 * @return   void
 */
void task_init(void)
{
    void *app_task_handle;

    os_msg_queue_create(&audio_io_queue_handle, "ioQ", BT_AUDIO_MAX_NUMBER_OF_IO_MESSAGE,
                        sizeof(T_IO_MSG));
    os_msg_queue_create(&audio_evt_queue_handle, "evtQ", BT_AUDIO_MAX_NUMBER_OF_EVENT_MESSAGE,
                        sizeof(unsigned char));

    app_init_timer(audio_evt_queue_handle, AUDIO_MAX_NUMBER_OF_APP_TIMER_MODULE);

    os_task_create(&app_task_handle, "audio_demo_main_task", audio_demo_main_task, NULL, 1024 * 3, 1);
}

/**
 * @brief    Entry of APP code
 * @return   int (To avoid compile warning)
 */
int main(void)
{
    board_init();
    driver_init();
    task_init();
    framework_init();
    app_audio_init();
    app_audio_passthrough_init();
    app_audio_demo_cmd_register();
    os_sched_start();

    return 0;
}
/** @} */ /* End of group BT_AUDIO_MAIN */
```
